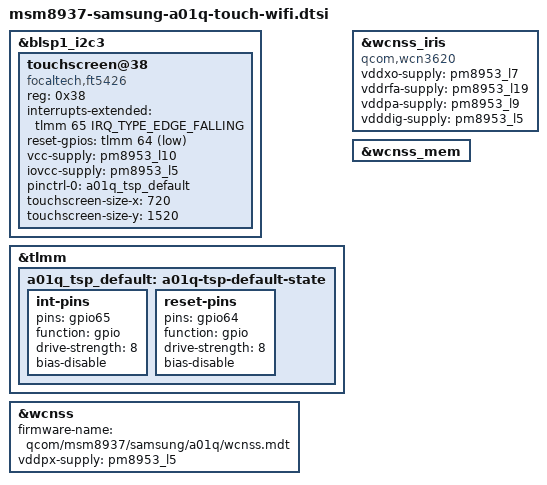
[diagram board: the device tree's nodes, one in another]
// SPDX-License-Identifier: GPL-2.0-only
/*
 * Samsung Galaxy A01 (a01q, SDM439): touchscreen and Wi-Fi/Bluetooth.
 *
 * Meant to be #included by the board file. Every value below was read from
 * the stock SDM439 DTB/DTBO (DTBO entry "QRD MP4", board-id 0xb/0xf9; the
 * touchscreen and WCNSS nodes are the same in all nine hardware revisions).
 *
 * The including board file must provide: tlmm, blsp1_i2c3 (from
 * msm8937.dtsi) and the PM8953 regulators pm8953_l5, l7, l9, l10 and l19.
 */

#include <dt-bindings/gpio/gpio.h>
#include <dt-bindings/interrupt-controller/irq.h>

&blsp1_i2c3 {
	status = "okay";

	/*
	 * Stock: "focaltech,ft5446" at 0x38, reset gpio64, irq gpio65
	 * (falling edge), vdd = L10, 10 points, 720x1520. The kernel has no
	 * FT5446 entry, so use FT5426, the closest one that is supported.
	 *
	 * Some units use a Goodix GT1x at 0x14 instead (stock probes both);
	 * this one is the Focaltech variant.
	 */
	touchscreen@38 {
		compatible = "focaltech,ft5426";
		reg = <0x38>;

		interrupts-extended = <&tlmm 65 IRQ_TYPE_EDGE_FALLING>;
		reset-gpios = <&tlmm 64 GPIO_ACTIVE_LOW>;

		vcc-supply = <&pm8953_l10>;
		iovcc-supply = <&pm8953_l5>;

		pinctrl-0 = <&a01q_tsp_default>;
		pinctrl-names = "default";

		touchscreen-size-x = <720>;
		touchscreen-size-y = <1520>;
	};
};

&tlmm {
	a01q_tsp_default: a01q-tsp-default-state {
		int-pins {
			pins = "gpio65";
			function = "gpio";
			drive-strength = <8>;
			bias-disable;
		};

		reset-pins {
			pins = "gpio64";
			function = "gpio";
			drive-strength = <8>;
			bias-disable;
		};
	};
};

/*
 * Stock: pronto v3, firmware "wcnss", rails vddxo = L7 (1.8 V),
 * vddrfa = L19 (1.3 V), vddpa = L9 (3.3 V), vdddig/vddpx = L5 (1.8 V),
 * WLAN pins gpio76-80.
 *
 * Firmware is not in linux-firmware: copy wcnss.mdt/.mbn/.b0x from the
 * stock "modem" partition (firmware-mnt) to the path below and
 * WCNSS_qcom_wlan_nv.bin to wlan/prima/ under /lib/firmware.
 */
&wcnss {
	firmware-name = "qcom/msm8937/samsung/a01q/wcnss.mdt";
	vddpx-supply = <&pm8953_l5>;

	status = "okay";
};

/*
 * The iris RF chip is not described in the stock DTB (it is detected at
 * run time). A01 is 2.4 GHz only, so WCN3620 is the first guess; if wcn36xx
 * fails to bring the radio up, try "qcom,wcn3660" or "qcom,wcn3660b".
 */
&wcnss_iris {
	compatible = "qcom,wcn3620";
	vddxo-supply = <&pm8953_l7>;
	vddrfa-supply = <&pm8953_l19>;
	vddpa-supply = <&pm8953_l9>;
	vdddig-supply = <&pm8953_l5>;
};

&wcnss_mem {
	status = "okay";
};
